AUTOSAR XML (schema 4-2-1)
package /MICROSAR/BswM_swc
  7 x mode declaration group:
    ESH_Mode: initial-mode=STARTUP
      5 x mode:
        STARTUP
        RUN
        POSTRUN
        WAKEUP
        SHUTDOWN
    ESH_RunRequest: initial-mode=RELEASED
      mode RELEASED
      mode REQUESTED
    BswMRteMDG_LIN3Schedule: initial-mode=LIN3_NULL
      7 x mode:
        LIN3_NULL
        LIN3_TABLE1
        LIN3_TABLE2
        LIN3_TABLE_E
        LIN3_MasterReq_SlaveResp_Table1
        LIN3_MasterReq_SlaveResp_Table2
        LIN3_MasterReq_SlaveResp
    BswMRteMDG_LIN1Schedule: initial-mode=LIN1_NULL
      7 x mode:
        LIN1_Table1
        LIN1_Table2
        LIN1_Table_E
        LIN1_MasterReq_SlaveResp_Table1
        LIN1_MasterReq_SlaveResp_Table2
        LIN1_NULL
        LIN1_MasterReq_SlaveResp
    BswMRteMDG_LIN2Schedule: initial-mode=LIN2_NULL
      5 x mode:
        LIN2_NULL
        LIN2_TABLE0
        LIN2_TABLE_E
        LIN2_MasterReq_SlaveResp_TABLE0
        LIN2_MasterReq_SlaveResp
    BswMRteMDG_LIN4Schedule: initial-mode=LIN4_NULL
      7 x mode:
        LIN4_NULL
        LIN4_MasterReq_SlaveResp_Table1
        LIN4_TABLE1
        LIN4_TABLE2
        LIN4_TABLE_E
        LIN4_MasterReq_SlaveResp_Table2
        LIN4_MasterReq_SlaveResp
    BswMRteMDG_LIN5Schedule: initial-mode=LIN5_NULL
      7 x mode:
        LIN5_NULL
        LIN5_TABLE1
        LIN5_MasterReq_SlaveResp_Table1
        LIN5_MasterReq_SlaveResp_Table2
        LIN5_MasterReq_SlaveResp
        LIN5_TABLE2
        LIN5_TABLE_E
  data type mapping set BswMMappingSet  # Contains Mapping for ModeDeclarations Groups which are provided by BswM.
    mode-request-type-maps:
      implementation-data-type=BswM_ESH_Mode, mode-group=ESH_Mode
      implementation-data-type=BswM_ESH_RunRequest, mode-group=ESH_RunRequest
      implementation-data-type=BswM_BswMRteMDG_LIN3Schedule, mode-group=BswMRteMDG_LIN3Schedule
      implementation-data-type=BswM_BswMRteMDG_LIN1Schedule, mode-group=BswMRteMDG_LIN1Schedule
      implementation-data-type=BswM_BswMRteMDG_LIN2Schedule, mode-group=BswMRteMDG_LIN2Schedule
      implementation-data-type=BswM_BswMRteMDG_LIN4Schedule, mode-group=BswMRteMDG_LIN4Schedule
      implementation-data-type=BswM_BswMRteMDG_LIN5Schedule, mode-group=BswMRteMDG_LIN5Schedule
package /MICROSAR/BswM_swc/ComponentTypes
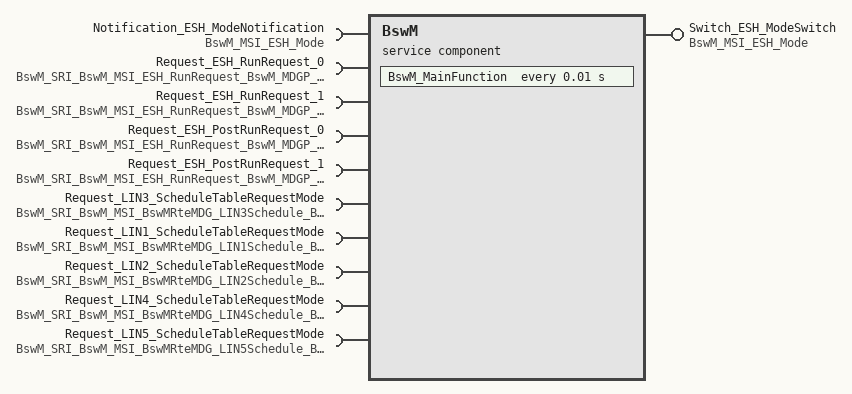
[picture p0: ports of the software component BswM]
  service sw component type BswM: category=SERVICE_COMPONENT
    provide port Switch_ESH_ModeSwitch: provided-interface=BswM_MSI_ESH_Mode
    10 x require port:
      Notification_ESH_ModeNotification: required-interface=BswM_MSI_ESH_Mode
      Request_ESH_RunRequest_0: nonqueued-receiver-com-spec{data-element=BswM_SRI_BswM_MSI_ESH_RunRequest_BswM_MDGP_ESH_RunRequest/requestedMode, handle-out-of-range-status=SILENT, init-value=RELEASED}, required-interface=BswM_SRI_BswM_MSI_ESH_RunRequest_BswM_MDGP_ESH_RunRequest
      Request_ESH_RunRequest_1: nonqueued-receiver-com-spec{data-element=BswM_SRI_BswM_MSI_ESH_RunRequest_BswM_MDGP_ESH_RunRequest/requestedMode, handle-out-of-range-status=SILENT, init-value=RELEASED}, required-interface=BswM_SRI_BswM_MSI_ESH_RunRequest_BswM_MDGP_ESH_RunRequest
      Request_ESH_PostRunRequest_0: nonqueued-receiver-com-spec{data-element=BswM_SRI_BswM_MSI_ESH_RunRequest_BswM_MDGP_ESH_RunRequest/requestedMode, handle-out-of-range-status=SILENT, init-value=RELEASED}, required-interface=BswM_SRI_BswM_MSI_ESH_RunRequest_BswM_MDGP_ESH_RunRequest
      Request_ESH_PostRunRequest_1: nonqueued-receiver-com-spec{data-element=BswM_SRI_BswM_MSI_ESH_RunRequest_BswM_MDGP_ESH_RunRequest/requestedMode, handle-out-of-range-status=SILENT, init-value=RELEASED}, required-interface=BswM_SRI_BswM_MSI_ESH_RunRequest_BswM_MDGP_ESH_RunRequest
      Request_LIN3_ScheduleTableRequestMode: nonqueued-receiver-com-spec{data-element=BswM_SRI_BswM_MSI_BswMRteMDG_LIN3Schedule_BswM_MDGP_BswMRteMDG_LIN3Schedule/requestedMode, handle-out-of-range-status=SILENT, init-value=LIN3_NULL}, required-interface=BswM_SRI_BswM_MSI_BswMRteMDG_LIN3Schedule_BswM_MDGP_BswMRteMDG_LIN3Schedule
      Request_LIN1_ScheduleTableRequestMode: nonqueued-receiver-com-spec{data-element=BswM_SRI_BswM_MSI_BswMRteMDG_LIN1Schedule_BswM_MDGP_BswMRteMDG_LIN1Schedule/requestedMode, handle-out-of-range-status=SILENT, init-value=LIN1_NULL}, required-interface=BswM_SRI_BswM_MSI_BswMRteMDG_LIN1Schedule_BswM_MDGP_BswMRteMDG_LIN1Schedule
      Request_LIN2_ScheduleTableRequestMode: nonqueued-receiver-com-spec{data-element=BswM_SRI_BswM_MSI_BswMRteMDG_LIN2Schedule_BswM_MDGP_BswMRteMDG_LIN2Schedule/requestedMode, handle-out-of-range-status=SILENT, init-value=LIN2_NULL}, required-interface=BswM_SRI_BswM_MSI_BswMRteMDG_LIN2Schedule_BswM_MDGP_BswMRteMDG_LIN2Schedule
      Request_LIN4_ScheduleTableRequestMode: nonqueued-receiver-com-spec{data-element=BswM_SRI_BswM_MSI_BswMRteMDG_LIN4Schedule_BswM_MDGP_BswMRteMDG_LIN4Schedule/requestedMode, handle-out-of-range-status=SILENT, init-value=LIN4_NULL}, required-interface=BswM_SRI_BswM_MSI_BswMRteMDG_LIN4Schedule_BswM_MDGP_BswMRteMDG_LIN4Schedule
      Request_LIN5_ScheduleTableRequestMode: nonqueued-receiver-com-spec{data-element=BswM_SRI_BswM_MSI_BswMRteMDG_LIN5Schedule_BswM_MDGP_BswMRteMDG_LIN5Schedule/requestedMode, handle-out-of-range-status=SILENT, init-value=LIN5_NULL}, required-interface=BswM_SRI_BswM_MSI_BswMRteMDG_LIN5Schedule_BswM_MDGP_BswMRteMDG_LIN5Schedule
    behavior BswMInternalBehavior: data-type-mapping=BswMMappingSet, handle-termination-and-restart=NO-SUPPORT, included-data-type-set=data-type=[BswM_ESH_Mode, BswM_ESH_RunRequest, BswM_BswMRteMDG_LIN3Schedule, BswM_BswMRteMDG_LIN1Schedule, BswM_BswMRteMDG_LIN2Schedule, BswM_BswMRteMDG_LIN4Schedule, BswM_BswMRteMDG_LIN5Schedule]
      timing event Timer_BswM_MainFunction: start-on-event=BswM_MainFunction, period=0.01
      5 x data received event:
        DataReceivedEvent_BswM_Read_LIN3_ScheduleTableRequestMode_Request_LIN3_ScheduleTableRequestMode_requestedMode: start-on-event=BswM_Read_LIN3_ScheduleTableRequestMode, data=Request_LIN3_ScheduleTableRequestMode.requestedMode
        DataReceivedEvent_BswM_Read_LIN1_ScheduleTableRequestMode_Request_LIN1_ScheduleTableRequestMode_requestedMode: start-on-event=BswM_Read_LIN1_ScheduleTableRequestMode, data=Request_LIN1_ScheduleTableRequestMode.requestedMode
        DataReceivedEvent_BswM_Read_LIN2_ScheduleTableRequestMode_Request_LIN2_ScheduleTableRequestMode_requestedMode: start-on-event=BswM_Read_LIN2_ScheduleTableRequestMode, data=Request_LIN2_ScheduleTableRequestMode.requestedMode
        DataReceivedEvent_BswM_Read_LIN4_ScheduleTableRequestMode_Request_LIN4_ScheduleTableRequestMode_requestedMode: start-on-event=BswM_Read_LIN4_ScheduleTableRequestMode, data=Request_LIN4_ScheduleTableRequestMode.requestedMode
        DataReceivedEvent_BswM_Read_LIN5_ScheduleTableRequestMode_Request_LIN5_ScheduleTableRequestMode_requestedMode: start-on-event=BswM_Read_LIN5_ScheduleTableRequestMode, data=Request_LIN5_ScheduleTableRequestMode.requestedMode
      port-api-options:
        enable-take-address=true, indirect-api=false, port=Switch_ESH_ModeSwitch
        enable-take-address=true, indirect-api=false, port=Notification_ESH_ModeNotification
        enable-take-address=true, indirect-api=false, port=Request_ESH_RunRequest_0
        enable-take-address=true, indirect-api=false, port=Request_ESH_RunRequest_1
        enable-take-address=true, indirect-api=false, port=Request_ESH_PostRunRequest_0
        enable-take-address=true, indirect-api=false, port=Request_ESH_PostRunRequest_1
        enable-take-address=true, indirect-api=false, port=Request_LIN3_ScheduleTableRequestMode
        enable-take-address=true, indirect-api=false, port=Request_LIN1_ScheduleTableRequestMode
        enable-take-address=true, indirect-api=false, port=Request_LIN2_ScheduleTableRequestMode
        enable-take-address=true, indirect-api=false, port=Request_LIN4_ScheduleTableRequestMode
        enable-take-address=true, indirect-api=false, port=Request_LIN5_ScheduleTableRequestMode
      6 x runnable:
        BswM_MainFunction: mode-access-point=Notification_ESH_ModeNotification.BswM_MDGP_ESH_Mode
          data-receive-point-by-arguments:
            4 x access:
              DataReceivePointBswM_MainFunction_Request_ESH_RunRequest_0_requestedMode: accessed-variable=Request_ESH_RunRequest_0.requestedMode
              DataReceivePointBswM_MainFunction_Request_ESH_RunRequest_1_requestedMode: accessed-variable=Request_ESH_RunRequest_1.requestedMode
              DataReceivePointBswM_MainFunction_Request_ESH_PostRunRequest_0_requestedMode: accessed-variable=Request_ESH_PostRunRequest_0.requestedMode
              DataReceivePointBswM_MainFunction_Request_ESH_PostRunRequest_1_requestedMode: accessed-variable=Request_ESH_PostRunRequest_1.requestedMode
          mode switch point ModeSwitchPointBswM_MainFunction_Switch_ESH_ModeSwitch_BswM_MDGP_ESH_Mode: mode-group=Switch_ESH_ModeSwitch.BswM_MDGP_ESH_Mode
        BswM_Read_LIN3_ScheduleTableRequestMode: can-be-invoked-concurrently=true
          data-receive-point-by-arguments:
            access DataReceivePointBswM_Read_LIN3_ScheduleTableRequestMode_Request_LIN3_ScheduleTableRequestMode_requestedMode: accessed-variable=Request_LIN3_ScheduleTableRequestMode.requestedMode
        BswM_Read_LIN1_ScheduleTableRequestMode: can-be-invoked-concurrently=true
          data-receive-point-by-arguments:
            access DataReceivePointBswM_Read_LIN1_ScheduleTableRequestMode_Request_LIN1_ScheduleTableRequestMode_requestedMode: accessed-variable=Request_LIN1_ScheduleTableRequestMode.requestedMode
        BswM_Read_LIN2_ScheduleTableRequestMode: can-be-invoked-concurrently=true
          data-receive-point-by-arguments:
            access DataReceivePointBswM_Read_LIN2_ScheduleTableRequestMode_Request_LIN2_ScheduleTableRequestMode_requestedMode: accessed-variable=Request_LIN2_ScheduleTableRequestMode.requestedMode
        BswM_Read_LIN4_ScheduleTableRequestMode: can-be-invoked-concurrently=true
          data-receive-point-by-arguments:
            access DataReceivePointBswM_Read_LIN4_ScheduleTableRequestMode_Request_LIN4_ScheduleTableRequestMode_requestedMode: accessed-variable=Request_LIN4_ScheduleTableRequestMode.requestedMode
        BswM_Read_LIN5_ScheduleTableRequestMode: can-be-invoked-concurrently=true
          data-receive-point-by-arguments:
            access DataReceivePointBswM_Read_LIN5_ScheduleTableRequestMode_Request_LIN5_ScheduleTableRequestMode_requestedMode: accessed-variable=Request_LIN5_ScheduleTableRequestMode.requestedMode
  swc implementation BswMImplementation: programming-language=C, behavior=BswMInternalBehavior
package /MICROSAR/BswM_swc/DataTypes
  7 x impl type, all with category=TYPE_REFERENCE, range raw 0..255, implementation-data-type=uint8:
    BswM_ESH_Mode: compu {0=STARTUP, 1=RUN, 2=POSTRUN, 3=WAKEUP, 4=SHUTDOWN}  # Unique value for each user
    BswM_ESH_RunRequest: compu {0=RELEASED, 1=REQUESTED}  # Unique value for each user
    BswM_BswMRteMDG_LIN3Schedule: compu {0=LIN3_NULL, 1=LIN3_TABLE1, 2=LIN3_TABLE2, 3=LIN3_TABLE_E, 4=LIN3_MasterReq_SlaveResp_Table1, 5=LIN3_MasterReq_SlaveResp_Table2, 6=LIN3_MasterReq_SlaveResp}  # Unique value for each user
    BswM_BswMRteMDG_LIN1Schedule: compu {1=LIN1_Table1, 2=LIN1_Table2, 3=LIN1_Table_E, 4=LIN1_MasterReq_SlaveResp_Table1, 5=LIN1_MasterReq_SlaveResp_Table2, 0=LIN1_NULL, 6=LIN1_MasterReq_SlaveResp}  # Unique value for each user
    BswM_BswMRteMDG_LIN2Schedule: compu {0=LIN2_NULL, 1=LIN2_TABLE0, 2=LIN2_TABLE_E, 3=LIN2_MasterReq_SlaveResp_TABLE0, 4=LIN2_MasterReq_SlaveResp}  # Unique value for each user
    BswM_BswMRteMDG_LIN4Schedule: compu {0=LIN4_NULL, 4=LIN4_MasterReq_SlaveResp_Table1, 1=LIN4_TABLE1, 2=LIN4_TABLE2, 3=LIN4_TABLE_E, 5=LIN4_MasterReq_SlaveResp_Table2, 6=LIN4_MasterReq_SlaveResp}  # Unique value for each user
    BswM_BswMRteMDG_LIN5Schedule: compu {0=LIN5_NULL, 1=LIN5_TABLE1, 4=LIN5_MasterReq_SlaveResp_Table1, 5=LIN5_MasterReq_SlaveResp_Table2, 6=LIN5_MasterReq_SlaveResp, 2=LIN5_TABLE2, 3=LIN5_TABLE_E}  # Unique value for each user
package /MICROSAR/BswM_swc/Interfaces
  mode switch interface BswM_MSI_ESH_Mode: is-service=true, service-kind=BASIC-SOFTWARE-MODE-MANAGER
    mode group BswM_MDGP_ESH_Mode: type=ESH_Mode
  sender receiver interface BswM_SRI_BswM_MSI_ESH_Mode_BswM_MDGP_ESH_Mode: is-service=true, service-kind=BASIC-SOFTWARE-MODE-MANAGER
    data requestedMode: type=BswM_ESH_Mode
  mode switch interface BswM_MSI_ESH_RunRequest: is-service=true, service-kind=BASIC-SOFTWARE-MODE-MANAGER
    mode group BswM_MDGP_ESH_RunRequest: type=ESH_RunRequest
  sender receiver interface BswM_SRI_BswM_MSI_ESH_RunRequest_BswM_MDGP_ESH_RunRequest: is-service=true, service-kind=BASIC-SOFTWARE-MODE-MANAGER
    data requestedMode: type=BswM_ESH_RunRequest
  mode switch interface BswM_MSI_BswMRteMDG_LIN3Schedule: is-service=true, service-kind=BASIC-SOFTWARE-MODE-MANAGER
    mode group BswM_MDGP_BswMRteMDG_LIN3Schedule: type=BswMRteMDG_LIN3Schedule
  sender receiver interface BswM_SRI_BswM_MSI_BswMRteMDG_LIN3Schedule_BswM_MDGP_BswMRteMDG_LIN3Schedule: is-service=true, service-kind=BASIC-SOFTWARE-MODE-MANAGER
    data requestedMode: type=BswM_BswMRteMDG_LIN3Schedule
  mode switch interface BswM_MSI_BswMRteMDG_LIN1Schedule: is-service=true, service-kind=BASIC-SOFTWARE-MODE-MANAGER
    mode group BswM_MDGP_BswMRteMDG_LIN1Schedule: type=BswMRteMDG_LIN1Schedule
  sender receiver interface BswM_SRI_BswM_MSI_BswMRteMDG_LIN1Schedule_BswM_MDGP_BswMRteMDG_LIN1Schedule: is-service=true, service-kind=BASIC-SOFTWARE-MODE-MANAGER
    data requestedMode: type=BswM_BswMRteMDG_LIN1Schedule
  mode switch interface BswM_MSI_BswMRteMDG_LIN2Schedule: is-service=true, service-kind=BASIC-SOFTWARE-MODE-MANAGER
    mode group BswM_MDGP_BswMRteMDG_LIN2Schedule: type=BswMRteMDG_LIN2Schedule
  sender receiver interface BswM_SRI_BswM_MSI_BswMRteMDG_LIN2Schedule_BswM_MDGP_BswMRteMDG_LIN2Schedule: is-service=true, service-kind=BASIC-SOFTWARE-MODE-MANAGER
    data requestedMode: type=BswM_BswMRteMDG_LIN2Schedule
  mode switch interface BswM_MSI_BswMRteMDG_LIN4Schedule: is-service=true, service-kind=BASIC-SOFTWARE-MODE-MANAGER
    mode group BswM_MDGP_BswMRteMDG_LIN4Schedule: type=BswMRteMDG_LIN4Schedule
  sender receiver interface BswM_SRI_BswM_MSI_BswMRteMDG_LIN4Schedule_BswM_MDGP_BswMRteMDG_LIN4Schedule: is-service=true, service-kind=BASIC-SOFTWARE-MODE-MANAGER
    data requestedMode: type=BswM_BswMRteMDG_LIN4Schedule
  mode switch interface BswM_MSI_BswMRteMDG_LIN5Schedule: is-service=true, service-kind=BASIC-SOFTWARE-MODE-MANAGER
    mode group BswM_MDGP_BswMRteMDG_LIN5Schedule: type=BswMRteMDG_LIN5Schedule
  sender receiver interface BswM_SRI_BswM_MSI_BswMRteMDG_LIN5Schedule_BswM_MDGP_BswMRteMDG_LIN5Schedule: is-service=true, service-kind=BASIC-SOFTWARE-MODE-MANAGER
    data requestedMode: type=BswM_BswMRteMDG_LIN5Schedule
